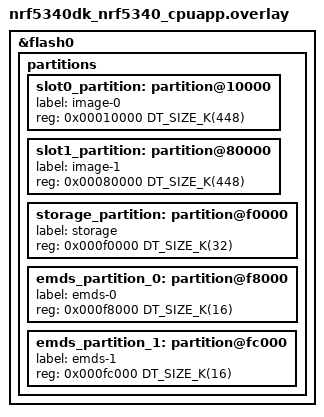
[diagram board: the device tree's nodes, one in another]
/delete-node/ &storage_partition;
/delete-node/ &slot0_partition;
/delete-node/ &slot1_partition;

&flash0 {
	partitions {
		slot0_partition: partition@10000 {
			label = "image-0";
			reg = <0x00010000 DT_SIZE_K(448)>;
		};

		slot1_partition: partition@80000 {
			label = "image-1";
			reg = <0x00080000 DT_SIZE_K(448)>;
		};

		storage_partition: partition@f0000 {
			label = "storage";
			reg = <0x000f0000 DT_SIZE_K(32)>;
		};

		emds_partition_0: partition@f8000 {
			label = "emds-0";
			reg = <0x000f8000 DT_SIZE_K(16)>;
		};

		emds_partition_1: partition@fc000 {
			label = "emds-1";
			reg = <0x000fc000 DT_SIZE_K(16)>;
		};
	};
};
